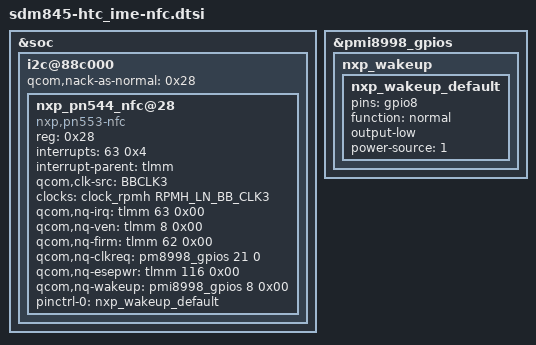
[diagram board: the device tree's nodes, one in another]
&soc {
	i2c@88c000 { /* i2c QUP3 */
	qcom,nack-as-normal = <0x28>;
	nxp_pn544_nfc@28 {
		/*Common*/
		compatible = "nxp,pn553-nfc";
		reg = <0x28>;
		interrupts = <63 0x4>;
		interrupt-parent = <&tlmm>;
		interrupt-names = "nfc_irq";
		clock-names = "ref_clk";
		qcom,clk-src = "BBCLK3";
		clocks = <&clock_rpmh RPMH_LN_BB_CLK3>;
		qcom,nq-irq = <&tlmm 63 0x00>;
		qcom,nq-ven = <&tlmm 8 0x00>;
		qcom,nq-firm = <&tlmm 62 0x00>;
		qcom,nq-clkreq = <&pm8998_gpios 21 0>;
		qcom,nq-esepwr = <&tlmm 116 0x00>;
		qcom,nq-wakeup = <&pmi8998_gpios 8 0x00>;
		pinctrl-names = "default";
                pinctrl-0 = <&nxp_wakeup_default>;
		};
	};
};

&pmi8998_gpios {
        nxp_wakeup { /* NXP WAKEUP */
                nxp_wakeup_default: nxp_wakeup_default {
                        pins = "gpio8";
                        function = "normal";
                        output-low;
                        power-source = <1>;
                };
        };
};
